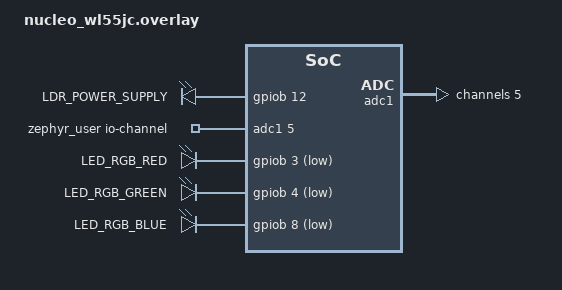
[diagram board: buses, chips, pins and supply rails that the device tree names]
#include <zephyr/dt-bindings/adc/adc.h>
#include <zephyr/dt-bindings/gpio/gpio.h>

/ {
    aliases {
        sw1 = &user_button_2;

        led-red = &led_red_node;
        led-green = &led_green_node;
        led-blue = &led_blue_node;

        analog-in-pin = &zephyr_user;

        ldr-pwr = &ldr_pwr_node;
    };

    ldr_pwr_supply {
        compatible = "gpio-leds";
        ldr_pwr_node: ldr_pwr_node {
            gpios = <&gpiob 12 GPIO_ACTIVE_HIGH>;
            label = "LDR_POWER_SUPPLY";
        };
    };

    zephyr_user: zephyr,user {
        io-channels = <&adc1 5>;
    };

    rgb_leds {
        compatible = "gpio-leds";

        led_red_node: led_red_node {
            gpios = <&gpiob 3 GPIO_ACTIVE_LOW>;
            label = "LED_RGB_RED";
        };

        led_green_node: led_green_node {
            gpios = <&gpiob 4 GPIO_ACTIVE_LOW>;
            label = "LED_RGB_GREEN";
        };

        led_blue_node: led_blue_node {
            gpios = <&gpiob 8 GPIO_ACTIVE_LOW>;
            label = "LED_RGB_BLUE";
        };

    };

};

&adc1 {
    status = "okay";
    #address-cells = <1>;
    #size-cells = <0>;

    channel@5 {
        reg = <5>;
        zephyr,gain = "ADC_GAIN_1";
        zephyr,reference = "ADC_REF_INTERNAL";
        zephyr,acquisition-time = <ADC_ACQ_TIME_DEFAULT>;
        zephyr,resolution = <12>;
    };
};

